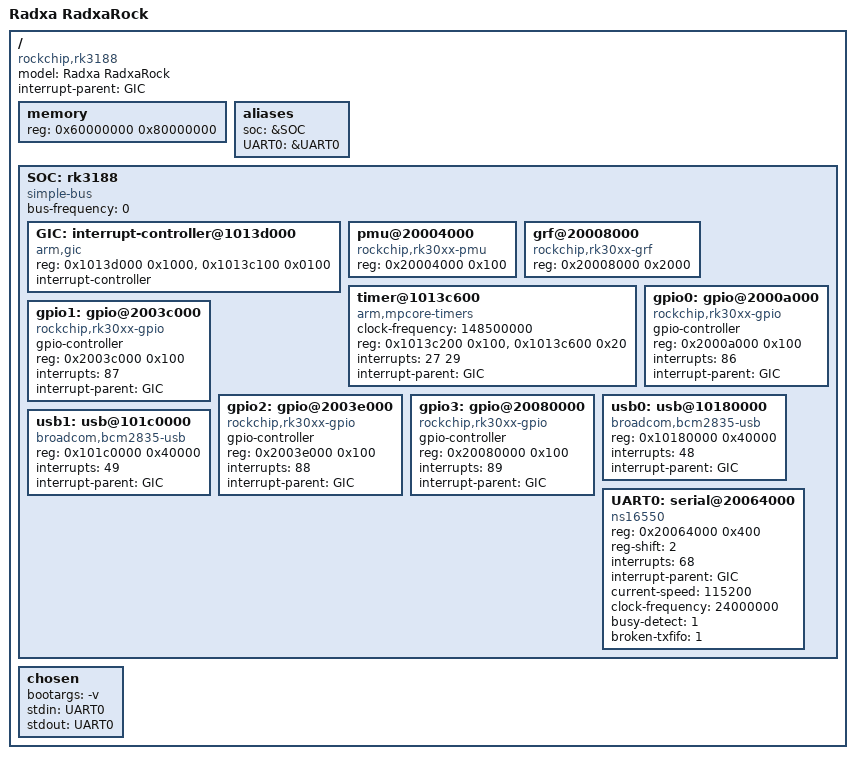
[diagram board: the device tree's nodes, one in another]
/*-
 * Copyright (c) 2013 Ganbold Tsagaankhuu <ganbold@gmail.com>
 * All rights reserved.
 *
 * Redistribution and use in source and binary forms, with or without
 * modification, are permitted provided that the following conditions
 * are met:
 * 1. Redistributions of source code must retain the above copyright
 *    notice, this list of conditions and the following disclaimer.
 * 2. Redistributions in binary form must reproduce the above copyright
 *    notice, this list of conditions and the following disclaimer in the
 *    documentation and/or other materials provided with the distribution.
 *
 * THIS SOFTWARE IS PROVIDED BY THE AUTHOR AND CONTRIBUTORS ``AS IS'' AND
 * ANY EXPRESS OR IMPLIED WARRANTIES, INCLUDING, BUT NOT LIMITED TO, THE
 * IMPLIED WARRANTIES OF MERCHANTABILITY AND FITNESS FOR A PARTICULAR PURPOSE
 * ARE DISCLAIMED.  IN NO EVENT SHALL THE AUTHOR OR CONTRIBUTORS BE LIABLE
 * FOR ANY DIRECT, INDIRECT, INCIDENTAL, SPECIAL, EXEMPLARY, OR CONSEQUENTIAL
 * DAMAGES (INCLUDING, BUT NOT LIMITED TO, PROCUREMENT OF SUBSTITUTE GOODS
 * OR SERVICES; LOSS OF USE, DATA, OR PROFITS; OR BUSINESS INTERRUPTION)
 * HOWEVER CAUSED AND ON ANY THEORY OF LIABILITY, WHETHER IN CONTRACT, STRICT
 * LIABILITY, OR TORT (INCLUDING NEGLIGENCE OR OTHERWISE) ARISING IN ANY WAY
 * OUT OF THE USE OF THIS SOFTWARE, EVEN IF ADVISED OF THE POSSIBILITY OF
 * SUCH DAMAGE.
 *
 * $FreeBSD$
 */

/dts-v1/;

/ {
	model = "Radxa RadxaRock";
	compatible = "rockchip,rk3188";
	#address-cells = <1>;
	#size-cells = <1>;

	interrupt-parent = <&GIC>;

	memory {
		device_type = "memory";
		reg = < 0x60000000 0x80000000 >;	/* 2GB RAM */
	};

	aliases {
		soc = &SOC;
		UART0 = &UART0;
	};

	SOC: rk3188 {
		#address-cells = <1>;
		#size-cells = <1>;
		compatible = "simple-bus";
		ranges;
		bus-frequency = <0>;

		GIC: interrupt-controller@1013d000 {
			compatible = "arm,gic";
			reg =	<0x1013d000 0x1000>,	/* Distributor Registers */
				<0x1013c100 0x0100>;	/* CPU Interface Registers */
			interrupt-controller;
			#interrupt-cells = <1>;
		};

		pmu@20004000 {
			compatible = "rockchip,rk30xx-pmu";
			#address-cells = <1>;
			#size-cells = <1>;
			reg = <0x20004000 0x100>;
		};

		grf@20008000 {
			compatible = "rockchip,rk30xx-grf";
			#address-cells = <1>;
			#size-cells = <1>;
			reg = < 0x20008000 0x2000 >;
		};

		timer@1013c600 {
			compatible = "arm,mpcore-timers";
			#address-cells = <1>;
			#size-cells = <0>;
			clock-frequency = < 148500000 >;
			reg =	<0x1013c200 0x100>,	/* Global Timer Regs */
				<0x1013c600 0x20>; 	/* Private Timer Regs */
			interrupts = < 27 29 >;
			interrupt-parent = <&GIC>;
		};

		gpio0: gpio@2000a000 {
			compatible = "rockchip,rk30xx-gpio";
			gpio-controller;
			#gpio-cells = <2>;
			reg = <0x2000a000 0x100>;
			interrupts = <86>;
			interrupt-parent = <&GIC>;
		};

		gpio1: gpio@2003c000 {
			compatible = "rockchip,rk30xx-gpio";
			gpio-controller;
			#gpio-cells = <2>;
			reg = <0x2003c000 0x100>;
			interrupts = <87>;
			interrupt-parent = <&GIC>;
		};

		gpio2: gpio@2003e000 {
			compatible = "rockchip,rk30xx-gpio";
			gpio-controller;
			#gpio-cells = <2>;
			reg = <0x2003e000 0x100>;
			interrupts = <88>;
			interrupt-parent = <&GIC>;
		};

		gpio3: gpio@20080000 {
			compatible = "rockchip,rk30xx-gpio";
			gpio-controller;
			#gpio-cells = <2>;
			reg = <0x20080000 0x100>;
			interrupts = <89>;
			interrupt-parent = <&GIC>;
		};

		usb0: usb@10180000 {
			compatible = "broadcom,bcm2835-usb",
				     "broadcom,bcm2708-usb",
				     "synopsys,designware-hs-otg2";
			reg = <0x10180000 0x40000>;
			interrupts = <48>;
			interrupt-parent = <&GIC>;
			#address-cells = <1>;
			#size-cells = <0>;
		};

		usb1: usb@101c0000 {
			compatible = "broadcom,bcm2835-usb",
				     "broadcom,bcm2708-usb",
				     "synopsys,designware-hs-otg2";
			reg = <0x101c0000 0x40000>;
			interrupts = < 49 >;
			interrupt-parent = <&GIC>;
			#address-cells = <1>;
			#size-cells = <0>;
		};

		UART0: serial@20064000 {
			status = "okay";
			compatible = "ns16550";
			reg = <0x20064000 0x400>;
			reg-shift = <2>;
			interrupts = <68>;
			interrupt-parent = <&GIC>;
			current-speed = <115200>;
			clock-frequency = < 24000000 >;
			busy-detect = <1>;
			broken-txfifo = <1>;
		};
	};

	chosen {
		bootargs = "-v";
		stdin = "UART0";
		stdout = "UART0";
	};
};

